# STM32WB09 register map
File version: 1.0
Registers are 32-bit, read-write, reset 0x0 unless marked. A register's access mark holds for its fields unless they carry their own. Offsets are from the block's base; [hi:lo] are bit positions; {n}, {i} and the like mark numbered series; 'fields as' and 'values as' point back to an identical list.

## RNG
Base 0x48600000
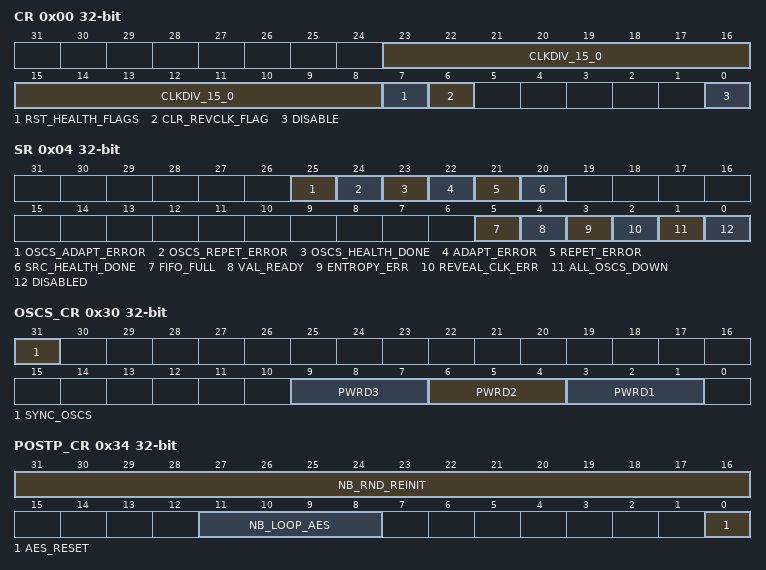
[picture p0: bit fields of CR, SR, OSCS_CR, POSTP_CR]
0x00 CR
  [23:8] CLKDIV_15_0, [7] RST_HEALTH_FLAGS, [6] CLR_REVCLK_FLAG, [0] DISABLE
0x04 SR
  [25] OSCS_ADAPT_ERROR, [24] OSCS_REPET_ERROR, [23] OSCS_HEALTH_DONE, [22] ADAPT_ERROR, [21] REPET_ERROR, [20] SRC_HEALTH_DONE, [5] FIFO_FULL, [4] VAL_READY, [3] ENTROPY_ERR, [2] REVEAL_CLK_ERR, [1] ALL_OSCS_DOWN, [0] DISABLED
0x08 VAL
  [31:0] RND_VAL
0x30 OSCS_CR
  [31] SYNC_OSCS, [9:7] PWRD3, [6:4] PWRD2, [3:1] PWRD1
0x34 POSTP_CR
  [31:16] NB_RND_REINIT, [11:8] NB_LOOP_AES, [0] AES_RESET
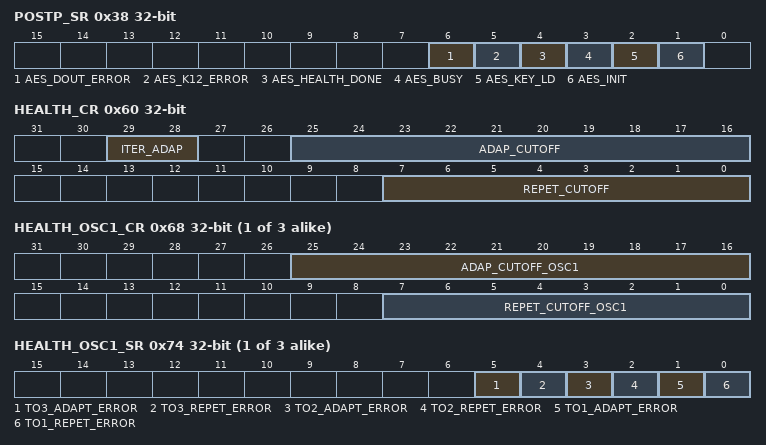
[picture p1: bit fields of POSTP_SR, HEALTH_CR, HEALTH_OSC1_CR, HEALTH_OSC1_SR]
0x38 POSTP_SR
  [6] AES_DOUT_ERROR, [5] AES_K12_ERROR, [4] AES_HEALTH_DONE, [3] AES_BUSY, [2] AES_KEY_LD, [1] AES_INIT
{0x40+4i} DEFKEY{i} (i=0..3)
  [31:0] RNG_DEFKEY{i}
0x60 HEALTH_CR
  [29:28] ITER_ADAP, [25:16] ADAP_CUTOFF, [7:0] REPET_CUTOFF
{0x64+4i} HEALTH_OSC{i}_CR (i=1..3)
  [25:16] ADAP_CUTOFF_OSC{i}, [7:0] REPET_CUTOFF_OSC{i}
{0x70+4i} HEALTH_OSC{i}_SR (i=1..3)
  [5] TO3_ADAPT_ERROR, [4] TO3_REPET_ERROR, [3] TO2_ADAPT_ERROR, [2] TO2_REPET_ERROR, [1] TO1_ADAPT_ERROR, [0] TO1_REPET_ERROR
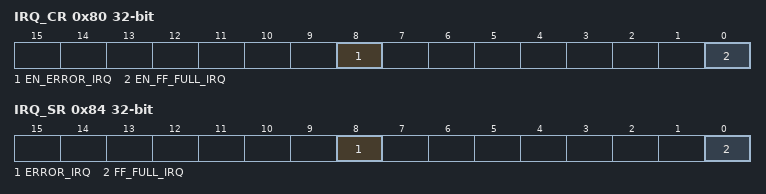
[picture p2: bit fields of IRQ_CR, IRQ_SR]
0x80 IRQ_CR
  [8] EN_ERROR_IRQ, [0] EN_FF_FULL_IRQ
0x84 IRQ_SR
  [8] ERROR_IRQ, [0] FF_FULL_IRQ

## DMA1
Base 0x48700000
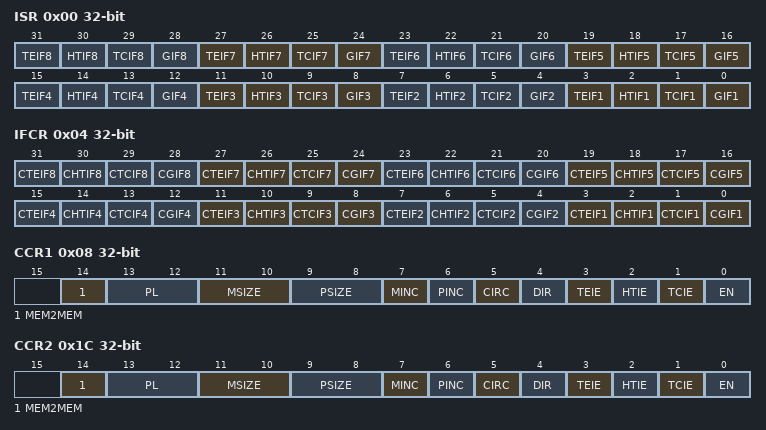
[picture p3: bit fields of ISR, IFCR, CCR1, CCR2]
0x00 ISR
  [4n-1] TEIF{n} (n=1..8), [4n-2] HTIF{n} (n=1..8), [4n-3] TCIF{n} (n=1..8), [4n-4] GIF{n} (n=1..8)
0x04 IFCR
  [4n-1] CTEIF{n} (n=1..8), [4n-2] CHTIF{n} (n=1..8), [4n-3] CTCIF{n} (n=1..8), [4n-4] CGIF{n} (n=1..8)
0x08 CCR1 — DMA channel x configuration register
  [14] MEM2MEM, [13:12] PL, [11:10] MSIZE, [9:8] PSIZE, [7] MINC, [6] PINC, [5] CIRC, [4] DIR, [3] TEIE, [2] HTIE, [1] TCIE, [0] EN
0x0C CNDTR1 — DMA channel x number of data register
  [15:0] NDT
0x10 CPAR1 — DMA channel x peripheral address register
  [31:0] PA
{0x0+0x14*i} CMAR{i} (i=1..8) — DMA channel x memory address register
  [31:0] MA
0x1C CCR2 — DMA channel x configuration register
  fields as CCR1
0x20 CNDTR2 — DMA channel x number of data register
  [15:0] NDT
0x24 CPAR2 — DMA channel x peripheral address register
  [31:0] PA
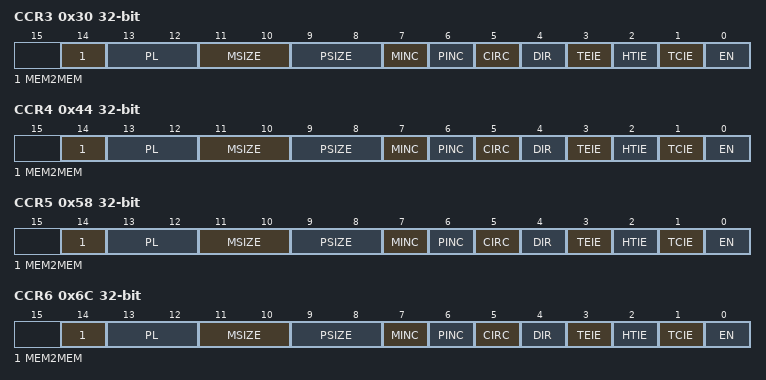
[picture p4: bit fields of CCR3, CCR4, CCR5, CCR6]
0x30 CCR3 — DMA channel x configuration register
  fields as CCR1
0x34 CNDTR3 — DMA channel x number of data register
  [15:0] NDT
0x38 CPAR3 — DMA channel x peripheral address register
  [31:0] PA
0x44 CCR4 — DMA channel x configuration register
  fields as CCR1
0x48 CNDTR4 — DMA channel x number of data register
  [15:0] NDT
0x4C CPAR4 — DMA channel x peripheral address register
  [31:0] PA
0x58 CCR5 — DMA channel x configuration register
  fields as CCR1
0x5C CNDTR5 — DMA channel x number of data register
  [15:0] NDT
0x60 CPAR5 — DMA channel x peripheral address register
  [31:0] PA
0x6C CCR6 — DMA channel x configuration register
  fields as CCR1
0x70 CNDTR6 — DMA channel x number of data register
  [15:0] NDT
0x74 CPAR6 — DMA channel x peripheral address register
  [31:0] PA
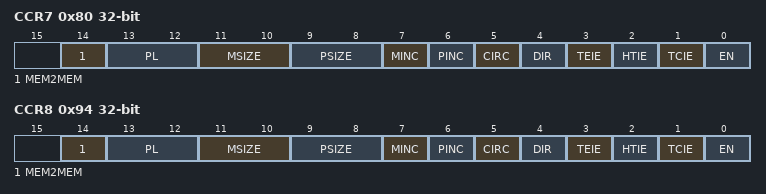
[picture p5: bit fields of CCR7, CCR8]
0x80 CCR7 — DMA channel x configuration register
  fields as CCR1
0x84 CNDTR7 — DMA channel x number of data register
  [15:0] NDT
0x88 CPAR7 — DMA channel x peripheral address register
  [31:0] PA
0x94 CCR8 — DMA channel x configuration register
  fields as CCR1
0x98 CNDTR8 — DMA channel x number of data register
  [15:0] NDT
0x9C CPAR8 — DMA channel x peripheral address register
  [31:0] PA

## DMAMUX1
Base 0x48800000
0x00 CxCR
  [4:0] DMAREQ_ID
{0x0+4i} C{i}CR (i=1..7)
  [4:0] DMAREQ_ID

## BLUE
Base 0x60000000
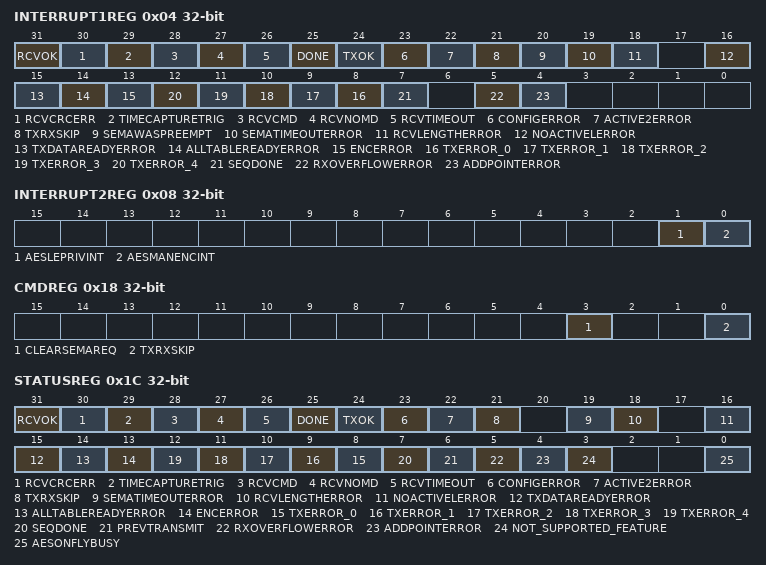
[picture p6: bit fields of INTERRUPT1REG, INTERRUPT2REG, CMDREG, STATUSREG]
0x04 INTERRUPT1REG
  [31] RCVOK, [30] RCVCRCERR, [29] TIMECAPTURETRIG, [28] RCVCMD, [27] RCVNOMD, [26] RCVTIMEOUT, [25] DONE, [24] TXOK, [23] CONFIGERROR, [22] ACTIVE2ERROR, [21] TXRXSKIP, [20] SEMAWASPREEMPT, [19] SEMATIMEOUTERROR, [18] RCVLENGTHERROR, [16] NOACTIVELERROR, [15] TXDATAREADYERROR, [14] ALLTABLEREADYERROR, [13] ENCERROR, [n+8] TXERROR_{n} (n=0..4), [7] SEQDONE, [5] RXOVERFLOWERROR, [4] ADDPOINTERROR
0x08 INTERRUPT2REG
  [1] AESLEPRIVINT, [0] AESMANENCINT
0x0C TIMEOUTDESTREG
  [1:0] DESTINATION
0x10 TIMEOUTREG
  [31:0] TIMEOUT
0x14 TIMERCAPTUREREG
  [31:0] TIMERCAPTURE
0x18 CMDREG
  [3] CLEARSEMAREQ, [0] TXRXSKIP
0x1C STATUSREG
  [31] RCVOK, [30] RCVCRCERR, [29] TIMECAPTURETRIG, [28] RCVCMD, [27] RCVNOMD, [26] RCVTIMEOUT, [25] DONE, [24] TXOK, [23] CONFIGERROR, [22] ACTIVE2ERROR, [21] TXRXSKIP, [19] SEMATIMEOUTERROR, [18] RCVLENGTHERROR, [16] NOACTIVELERROR, [15] TXDATAREADYERROR, [14] ALLTABLEREADYERROR, [13] ENCERROR, [n+8] TXERROR_{n} (n=0..4), [7] SEQDONE, [6] PREVTRANSMIT, [5] RXOVERFLOWERROR, [4] ADDPOINTERROR, [3] NOT_SUPPORTED_FEATURE, [0] AESONFLYBUSY
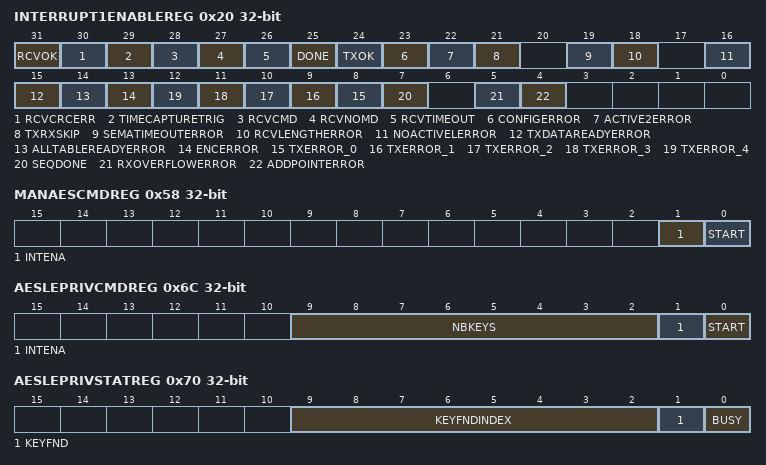
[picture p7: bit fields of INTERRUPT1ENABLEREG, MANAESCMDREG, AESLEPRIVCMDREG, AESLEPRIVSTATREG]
0x20 INTERRUPT1ENABLEREG
  [31] RCVOK, [30] RCVCRCERR, [29] TIMECAPTURETRIG, [28] RCVCMD, [27] RCVNOMD, [26] RCVTIMEOUT, [25] DONE, [24] TXOK, [23] CONFIGERROR, [22] ACTIVE2ERROR, [21] TXRXSKIP, [19] SEMATIMEOUTERROR, [18] RCVLENGTHERROR, [16] NOACTIVELERROR, [15] TXDATAREADYERROR, [14] ALLTABLEREADYERROR, [13] ENCERROR, [n+8] TXERROR_{n} (n=0..4), [7] SEQDONE, [5] RXOVERFLOWERROR, [4] ADDPOINTERROR
0x24 INTERRUPT1LATENCYREG
  [7:0] INTERRUPT1LATENCY
{0x28+4i} MANAESKEY{i}REG (i=0..3)
  [31:0] MANAESKEY_{32i+31}_{32i}
{0x38+4i} MANAESCLEARTEXT{i}REG (i=0..3)
  [31:0] AES
{0x48+4i} MANAESCIPHERTEXT{i}REG (i=0..3)
  [31:0] AES
0x58 MANAESCMDREG
  [1] INTENA, [0] START
0x5C MANAESSTATREG
  [0] BUSY
0x60 AESLEPRIVPOINTERREG
  [23:0] POINTER
0x64 AESLEPRIVHASHREG
  [23:0] HASH
0x68 AESLEPRIVPRANDREG
  [23:0] PRAND
0x6C AESLEPRIVCMDREG
  [9:2] NBKEYS, [1] INTENA, [0] START
0x70 AESLEPRIVSTATREG
  [9:2] KEYFNDINDEX, [1] KEYFND, [0] BUSY
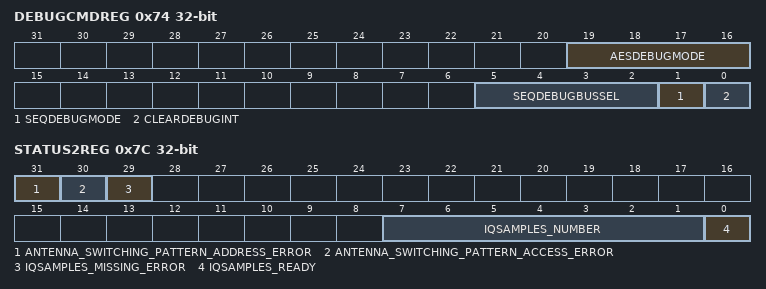
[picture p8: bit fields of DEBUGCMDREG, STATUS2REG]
0x74 DEBUGCMDREG
  [19:16] AESDEBUGMODE, [5:2] SEQDEBUGBUSSEL, [1] SEQDEBUGMODE, [0] CLEARDEBUGINT
0x7C STATUS2REG
  [31] ANTENNA_SWITCHING_PATTERN_ADDRESS_ERROR, [30] ANTENNA_SWITCHING_PATTERN_ACCESS_ERROR, [29] IQSAMPLES_MISSING_ERROR, [7:1] IQSAMPLES_NUMBER, [0] IQSAMPLES_READY
